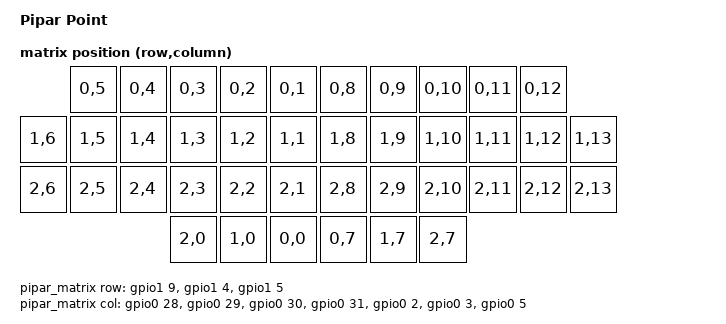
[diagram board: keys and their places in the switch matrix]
/dts-v1/;
#include <nordic/nrf52840_qiaa.dtsi>
#include <common/nordic/nrf52840_uf2_boot_mode.dtsi>

#include <dt-bindings/led/led.h>
#include <dt-bindings/zmk/matrix_transform.h>

#include "pipar_point-layouts.dtsi"
#include "pipar_point-pinctrl.dtsi"

&physical_layout0 {
    transform = <&matrix_transform0>;
};

/ {
  model = "Pipar Point";
  compatible = "piparkeyboards,pipar_point";

  chosen {
    zephyr,code-partition = &code_partition;
    zephyr,sram = &sram0;
    zephyr,flash = &flash0;
    zmk,backlight = &backlight;
    zmk,physical-layout = &physical_layout0;
    zmk,kscan = &pipar_matrix;
  };

  pipar_matrix: kscan {
    compatible = "zmk,kscan-gpio-matrix";
    wakeup-source;
    diode-direction = "col2row";
    col-gpios
    = <&gpio0 28 GPIO_ACTIVE_HIGH>
    , <&gpio0 29 GPIO_ACTIVE_HIGH>
    , <&gpio0 30 GPIO_ACTIVE_HIGH>
    , <&gpio0 31 GPIO_ACTIVE_HIGH>
    , <&gpio0 2 GPIO_ACTIVE_HIGH>
    , <&gpio0 3 GPIO_ACTIVE_HIGH>
    , <&gpio0 5 GPIO_ACTIVE_HIGH>
    ;
    row-gpios
    = <&gpio1 9 (GPIO_PULL_DOWN  | GPIO_ACTIVE_HIGH)>
    , <&gpio1 4 (GPIO_PULL_DOWN  | GPIO_ACTIVE_HIGH)>
    , <&gpio1 5 (GPIO_PULL_DOWN  | GPIO_ACTIVE_HIGH)>
    ;

  };
  
  matrix_transform0: keymap_transform_0 {
    compatible = "zmk,matrix-transform";
    columns = <14>;
    rows = <3>;
    map = <
             RC(0,5)  RC(0,4)  RC(0,3)  RC(0,2)  RC(0,1)    RC(0,8)  RC(0,9)   RC(0,10)  RC(0,11)  RC(0,12)
    RC(1,6)  RC(1,5)  RC(1,4)  RC(1,3)  RC(1,2)  RC(1,1)    RC(1,8)  RC(1,9)   RC(1,10)  RC(1,11)  RC(1,12)  RC(1,13)
    RC(2,6)  RC(2,5)  RC(2,4)  RC(2,3)  RC(2,2)  RC(2,1)    RC(2,8)  RC(2,9)   RC(2,10)  RC(2,11)  RC(2,12)  RC(2,13)
                               RC(2,0)  RC(1,0)  RC(0,0)    RC(0,7)  RC(1,7)   RC(2,7)
    >;
  };

  backlight: pwmleds {
    compatible = "pwm-leds";
    pwm_led_0 {
      pwms = <&pwm0 0 PWM_MSEC(10) PWM_POLARITY_NORMAL>;
    };
  };

};


&adc {
  status = "okay";
};

&gpiote {
  status = "okay";
};

&gpio0 {
  status = "okay";
};
&gpio1 {
  status = "okay";
};

zephyr_udc0: &usbd {
  status = "okay";
};

&pwm0 {
  status = "okay";
  pinctrl-0 = <&pwm0_default>;
  pinctrl-1 = <&pwm0_sleep>;
  pinctrl-names = "default", "sleep";
};

&i2c0 {
	compatible = "nordic,nrf-twim";
	status = "okay";
	pinctrl-0 = <&i2c0_default>;
	pinctrl-1 = <&i2c0_sleep>;
	pinctrl-names = "default", "sleep";

	npm1300: pmic@6b {
		compatible = "nordic,npm1300";
		reg = <0x6b>;

    npm1300_leds: leds {
			compatible = "nordic,npm1300-led";
			nordic,led0-mode = "error";
			nordic,led1-mode = "charging";
			nordic,led2-mode = "host";
		};
		regulators {
			compatible = "nordic,npm1300-regulator";

			buck1: BUCK1 {
				regulator-boot-off;
        status = "disabled";
			};

      buck2: BUCK2 {  
				regulator-min-microvolt = <3300000>;
				regulator-max-microvolt = <3300000>;
				regulator-boot-on;
        regulator-always-on;
			};  

			ldo1: LDO1 {
				status = "disabled";
			};

			ldo2: LDO2 {
				status = "disabled";
			};
		};

		charger: charger {
			compatible = "nordic,npm1300-charger";
      term-microvolt = <4200000>;          /* 4.2 V full charge */
      term-warm-microvolt = <4000000>;     /* 4.0 V if warm (JEITA region) */
      current-microamp = <500000>;         /* 0.2 C = 500 mA charge current */
      term-current-percent = <10>;         /* terminate when current ≤ 0.1 C = 250 mA */
      dischg-limit-microamp = <1000000>;   /* allow 1 A discharge */
      vbus-limit-microamp = <500000>;      /* USB current limit 500 mA */
      /* No thermistor (disable NTC) */
      thermistor-ohms = <0>;
      thermistor-beta = <0>;
			charging-enable;
		};
	};
};

&flash0 {
    /*
     * For more information, see:
     * http://docs.zephyrproject.org/latest/devices/dts/flash_partitions.html
     */
  partitions {
    compatible = "fixed-partitions";
    #address-cells = <1>;
    #size-cells = <1>;

    sd_partition: partition@0 {
      reg = <0x00000000 0x00026000>;
    };
    code_partition: partition@26000 {
      reg = <0x00026000 0x000c6000>;
    };

    /*
      * The flash starting at 0x000ec000 and ending at
      * 0x000f3fff is reserved for use by the application.
      */

    /*
      * Storage partition will be used by FCB/LittleFS/NVS
      * if enabled.
      */
    storage_partition: partition@ec000 {
      reg = <0x000ec000 0x00008000>;
    };

    boot_partition: partition@f4000 {
      reg = <0x000f4000 0x0000c000>;
    };
  };
};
